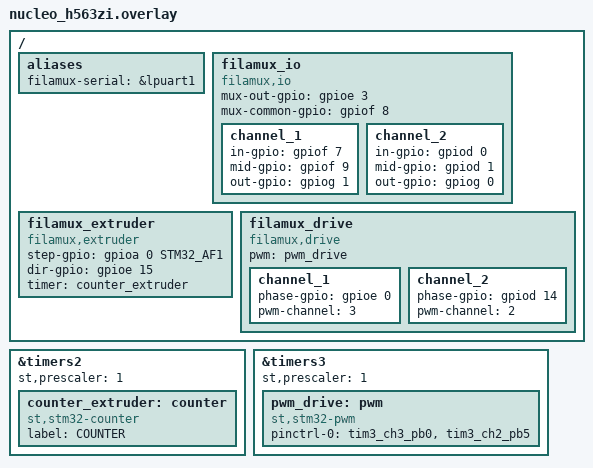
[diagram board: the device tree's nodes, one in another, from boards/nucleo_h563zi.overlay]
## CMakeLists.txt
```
#-------------------------------------------------------------------------------
# Zephyr Example Application
#
# Copyright (c) 2021 Nordic Semiconductor ASA
# SPDX-License-Identifier: Apache-2.0

cmake_minimum_required(VERSION 3.13.1)
find_package(Zephyr REQUIRED HINTS $ENV{ZEPHYR_BASE})

project(app LANGUAGES C)

target_sources(app 
    PRIVATE 
        src/main.c
        src/filamux.c
        src/filamux_io.c
        src/filamux_extruder.c
        src/filamux_serial.c
        src/filamux_counter.c
        src/state_machine.c
        src/filament_drive.c
)
```

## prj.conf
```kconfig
# Copyright (c) 2021 Nordic Semiconductor ASA
# SPDX-License-Identifier: Apache-2.0
#
# This file contains selected Kconfig options for the application.

CONFIG_DEBUG=y
CONFIG_LOG=y
CONFIG_APP_LOG_LEVEL_INF=y

CONFIG_MAIN_STACK_SIZE=4096

CONFIG_SMF=y
CONFIG_FILAMUX_PROTO_LIB=y
CONFIG_SERIAL=y
CONFIG_UART_INTERRUPT_DRIVEN=y
CONFIG_COUNTER=y
CONFIG_PWM=y
CONFIG_CRC=y
```

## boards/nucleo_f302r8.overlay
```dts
/*
 * Copyright (c) 2021 Nordic Semiconductor ASA
 * SPDX-License-Identifier: Apache-2.0
 */

/* This devicetree overlay file will be automatically picked by the Zephyr
 * build system when building the sample for the nucleo_f302r8 board. It shows
 * how the example-application can be built on sample boards already provided
 * by Zephyr.
 */

/ {
};

&gpioc {
	status = "okay";
};
```

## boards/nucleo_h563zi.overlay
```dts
#include <zephyr/dt-bindings/pinctrl/stm32-pinctrl.h>

/ {
    aliases {
        filamux-serial = &lpuart1;
    };

    filamux_io: filamux_io {
        compatible = "filamux,io";
        mux-out-gpio = <&gpioe 3 0>;
        mux-common-gpio = <&gpiof 8 0>;
        channel_1 {
            in-gpio = <&gpiof 7 0>;
            mid-gpio = <&gpiof 9 0>;
            out-gpio = <&gpiog 1 0>;
        };
        channel_2 {
            in-gpio = <&gpiod 0 0>;
            mid-gpio = <&gpiod 1 0>;
            out-gpio = <&gpiog 0 0>;
        };
    };

    filamux_extruder: filamux_extruder {
        compatible = "filamux,extruder";
        step-gpio = <&gpioa 0 STM32_AF1>; ///< TIM2_CH1
        dir-gpio = <&gpioe 15 0>;
        timer = <&counter_extruder>;
    };

    filamux_drive: filamux_drive {
        compatible = "filamux,drive";
        pwm = <&pwm_drive>;
        channel_1 {
            phase-gpio = <&gpioe 0 0>;
            pwm-channel = <3>;
        };
        channel_2 {
            phase-gpio = <&gpiod 14 0>;
            pwm-channel = <2>;
        };
    };
};

&timers2 {
    status = "okay";
    st,prescaler = <1>;
    counter_extruder: counter {
        compatible = "st,stm32-counter";
        status = "okay";
        label = "COUNTER";
    };
};

&timers3 {
    status = "okay";
    st,prescaler = <1>;
    pwm_drive: pwm {
        compatible = "st,stm32-pwm";
        status = "okay";
        pinctrl-0 = <&tim3_ch3_pb0 &tim3_ch2_pb5>;
        pinctrl-names = "default";
    };
};
```

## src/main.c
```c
/*
 * Copyright (c) 2021 Nordic Semiconductor ASA
 * SPDX-License-Identifier: Apache-2.0
 */

#include <zephyr/kernel.h>
#include <app_version.h>

#include <zephyr/logging/log.h>
LOG_MODULE_REGISTER(main, CONFIG_APP_LOG_LEVEL);

#include "filamux_counter.h"
#include "filamux.h"
#include "filamux_serial.h"
#include "filamux_io.h"
#include "state_machine.h"

void extruder_demo(struct filamux *filamux)
{
	filamux_extruder_set_speed(filamux->extruder, 1.0);
	k_sleep(K_MSEC(3000));
	LOG_INF("Feeding 10mm");
	filamux_extruder_feed(filamux->extruder, 100);
	k_sleep(K_MSEC(3000));
	LOG_INF("Feeding -5mm");
	filamux_extruder_set_speed(filamux->extruder, 0.5);
	filamux_extruder_feed(filamux->extruder, -50);
	k_sleep(K_MSEC(3000));
	LOG_INF("Feeding 20mm");
	filamux_extruder_set_speed(filamux->extruder, 2.0);
	filamux_extruder_feed(filamux->extruder, 200);
}

void drive_demo(struct filamux *filamux)
{
	LOG_INF("Setting drive to 1");
	set_active_filament_drive(filamux->drive, 1);
	set_filament_drive_feed(filamux->drive, 50);
	k_sleep(K_MSEC(1000));
	set_filament_drive_feed(filamux->drive, 100);
	k_sleep(K_MSEC(1000));
	set_filament_drive_feed(filamux->drive, -50);
	k_sleep(K_MSEC(1000));
	LOG_INF("Setting drive to 2");
	set_active_filament_drive(filamux->drive, 2);
	set_filament_drive_feed(filamux->drive, 50);
	k_sleep(K_MSEC(1000));
	set_filament_drive_feed(filamux->drive, 100);
	k_sleep(K_MSEC(1000));
	set_filament_drive_feed(filamux->drive, -50);
	k_sleep(K_MSEC(1000));
}

int main(void)
{
	int ret;

	printk("Zephyr Example Application %s\n", APP_VERSION_STRING);

	struct filamux *filamux = NULL;
	filamux_init(&filamux);
	LOG_INF("Initializing serial");
	filamux_serial_init(filamux);
	LOG_INF("Initializing io");
	io_init();
	set_filament_drive_feed(filamux->drive, 0);
	filamux_counter_set_current_spool(filamux->counter, 1);

	while (1) {
		filamux_fsm_run(filamux);
		// filamux_extruder_feed_continuous(filamux->extruder, -5);
		// drive_demo(filamux);
		//  extruder_demo(filamux);
		filamux_serial_process(filamux);
		k_msleep(100);

		/* Counting */
		filamux_counter_add(filamux->counter,
				    -filamux_extruder_pop_traveled_mm(filamux->extruder));
	}

	return 0;
}
```

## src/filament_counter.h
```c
#ifndef __FILAMENT_COUNTER_H_
#define __FILAMENT_COUNTER_H_

struct filament_counter;

/**
 * Allocate new filament counter
 */
int new_filament_counter(struct filament_counter **counter, unsigned int spools_count);

/**
 * Get used length of current filament spool
 * @returns -1 if no spool selected
 */
int get_current_filament_used(struct filament_counter *counter);

/**
 * Get used length of specified filament spool
 * @param index index of filament spool to fetch
 */
int get_filament_used(struct filament_counter *counter, unsigned int index);

/**
 * Set current spool to index
 * @param index which spool is used now
 */
int set_current_spool(struct filament_counter *counter, unsigned int index);

/**
 * Get current spool
 * @returns 0 if no spool selected
 */
int get_current_spool(struct filament_counter *counter);

#endif /* __FILAMENT_COUNTER_H_ */
```

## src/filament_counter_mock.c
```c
#include "filament_counter.h"
#include <stdint.h>
#include <zephyr/logging/log.h>
LOG_MODULE_REGISTER(counter, CONFIG_APP_LOG_LEVEL);

struct spool {
	unsigned int index;
	uint32_t used_length; ///< In mm
};

struct filament_counter {
	struct spool *current_spool; ///< Current spool. NULL means no spool.
	unsigned int spool_count;    ///< Number of spools
	struct spool *spools;
};

int new_filament_counter(struct filament_counter **counter, unsigned int spools_count)
{
	*counter = malloc(sizeof(struct filament_counter));
	if (!counter) {
		LOG_ERR("Could not allocate filament counter");
		return -1;
	}
	(*counter)->current_spool = NULL;
	(*counter)->spools = malloc(sizeof(struct spool[spools_count]));
	if (!(*counter)->spools) {
		LOG_ERR("Could not allocate spool buffers");
		return -1;
	}
	(*counter)->spool_count = spools_count;

	struct spool *spool = (*counter)->spools;
	for (int i = 0; i < spools_count; i++) {
		spool->index = i + 1;
		spool->used_length = 0;
		spool++;
	}

	return 0;
}

int get_current_filament_used(struct filament_counter *counter)
{
	if (!counter->current_spool) {
		LOG_ERR("No spool selected. Cannot get used length");
		return -1;
	}
	return counter->current_spool->used_length;
}

int get_filament_used(struct filament_counter *counter, unsigned int index)
{
	if (index > counter->spool_count || index == 0) {
		LOG_ERR("Invalid spool index: %d", index);
		return -1;
	}
	return counter->spools[index - 1].used_length;
}

int set_current_spool(struct filament_counter *counter, unsigned int index)
{
	if (index > counter->spool_count || index == 0) {
		LOG_ERR("Invalid spool index: %d", index);
		return -1;
	}
	counter->current_spool = &counter->spools[index - 1];
	LOG_INF("Current spool set to %d", index);
	return 0;
}

int get_current_spool(struct filament_counter *counter)
{
	if (!counter->current_spool) {
		return 0;
	}
	return counter->current_spool->index;
}
```

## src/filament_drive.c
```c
#include "filament_drive.h"
#include <zephyr/drivers/gpio.h>
#include <zephyr/drivers/pwm.h>
#include <zephyr/logging/log.h>
#include <stdlib.h>
LOG_MODULE_REGISTER(drive, CONFIG_APP_LOG_LEVEL);

struct filament_drive_channel {
	struct gpio_dt_spec ph_gpio;
	int pwm_channel;
};

struct filament_drive {
	unsigned int active_drive;
	unsigned int drive_count;

	struct filament_drive_channel *channel_active;
};

#define CHANNEL_DATA(node_id)                                                                      \
	{                                                                                          \
		.ph_gpio = GPIO_DT_SPEC_GET(node_id, phase_gpio),                                  \
		.pwm_channel = DT_PROP(node_id, pwm_channel),                                      \
	},

static struct filament_drive_channel channels[] = {
	DT_FOREACH_CHILD(DT_NODELABEL(filamux_drive), CHANNEL_DATA)};

static const struct device *pwm = DEVICE_DT_GET(DT_NODELABEL(pwm_drive));

int new_filament_drive(struct filament_drive **drive, unsigned int drive_count)
{
	*drive = malloc(sizeof(struct filament_drive));
	(*drive)->active_drive = 0;
	(*drive)->drive_count = sizeof(channels) / sizeof(struct filament_drive_channel);
	(*drive)->channel_active = NULL;
	gpio_pin_configure_dt(&channels[0].ph_gpio, GPIO_OUTPUT | GPIO_PUSH_PULL);
	gpio_pin_configure_dt(&channels[1].ph_gpio, GPIO_OUTPUT | GPIO_PUSH_PULL);
	return 0;
}

int get_active_filament_drive(struct filament_drive *drive)
{
	/* TODO check gpios */
	return drive->active_drive;
}

int set_active_filament_drive(struct filament_drive *drive, int drive_number)
{
	LOG_DBG("Setting filament drive to: %d", drive_number);
	if (drive_number < 0 || drive_number > drive->drive_count) {
		LOG_ERR("Invalid drive number: %d", drive_number);
		return -1;
	}
	if (drive->active_drive != 0) {
		LOG_DBG("Stopping current drive");
		set_filament_drive_feed(drive, 0);
	}
	drive->active_drive = drive_number;
	if (drive_number == 0) {
		drive->channel_active = NULL;
	} else {
		drive->channel_active = &channels[drive_number - 1];
	}
	LOG_DBG("Set active drive to %d", drive_number);
	return 0;
}

int set_filament_drive_feed(struct filament_drive *drive, int feed)
{
	if (drive->active_drive <= 0) {
		LOG_ERR("Cannot set drive feed when no drive is active");
		return -1;
	}
	if (drive->channel_active == NULL) {
		LOG_ERR("Cannot set drive. channel_active == NULL");
		return -1;
	}
	LOG_INF("Setting filament drive feed to %d", feed);
	bool is_reverse = feed < 0;
	unsigned int feed_abs = abs(feed);
	const uint32_t period = 10000;
	uint32_t pulse_width = period;
	if (feed_abs > 100) {
		LOG_ERR("cannot set feed to %d%. Capping to 100%");
	} else {
		LOG_DBG("Set feed to %d", feed);
		pulse_width = (feed_abs / 100.0) * period;
	}
	gpio_pin_set_dt(&drive->channel_active->ph_gpio, is_reverse);
	pwm_set(pwm, drive->channel_active->pwm_channel, period, pulse_width, PWM_POLARITY_NORMAL);
	return 0;
}
```

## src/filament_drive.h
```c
#ifndef __FILAMENT_DRIVE_H_
#define __FILAMENT_DRIVE_H_

#include "filamux.h"

struct filament_drive;

int new_filament_drive(struct filament_drive **drive, unsigned int drive_count);

/**
 * Check which filament drive is active
 * @returns active drive number. 0 if no drive active.
 */
int get_active_filament_drive(struct filament_drive *drive);

/**
 * Set active filament drive
 * @param drive_number number of drive to be activated. 0 to disable actieve drive.
 */
int set_active_filament_drive(struct filament_drive *drive, int drive_number);

/**
 * Set filament drive feed speed.
 * @param feed 0-100% of speed.
 */
int set_filament_drive_feed(struct filament_drive *drive, int feed);

#endif /* __FILAMENT_DRIVE_H_ */
```

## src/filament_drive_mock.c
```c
#include "filament_drive.h"
#include <zephyr/logging/log.h>
#include <stdlib.h>
LOG_MODULE_REGISTER(drive, CONFIG_APP_LOG_LEVEL);

struct filament_drive {
	unsigned int active_drive;
	unsigned int drive_count;
};

int new_filament_drive(struct filament_drive **drive, unsigned int drive_count)
{
	*drive = malloc(sizeof(struct filament_drive));
	(*drive)->active_drive = 0;
	(*drive)->drive_count = drive_count;
	return 0;
}

int get_active_filament_drive(struct filament_drive *drive)
{
	return drive->active_drive;
}

int set_active_filament_drive(struct filament_drive *drive, int drive_number)
{
	if (drive_number == 0 || drive_number > drive->drive_count) {
		LOG_ERR("Invalid drive number: %d", drive_number);
		return -1;
	}
	drive->active_drive = drive_number;
	LOG_DBG("Set active drive to %d", drive_number);
	return 0;
}

int set_filament_drive_feed(struct filament_drive *drive, int feed)
{
	LOG_DBG("Set feed to %d", feed);
	return 0;
}
```

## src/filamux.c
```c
#include "filamux.h"
#include <zephyr/logging/log.h>
LOG_MODULE_REGISTER(core, CONFIG_APP_LOG_LEVEL);

#define SPOOLS_COUNT 2

int filamux_init(struct filamux **o)
{
	*o = malloc(sizeof(struct filamux));
	new_filament_counter(&(*o)->counter, SPOOLS_COUNT);
	new_filament_drive(&(*o)->drive, SPOOLS_COUNT);
	filamux_extruder_init(&(*o)->extruder);
	filamux_fsm_init(*o);

	/* TODO set target spool to current from IO */
	(*o)->target_spool = 0;

	(*o)->extruder_req.distance = 0;
	(*o)->extruder_req.speed = 0;
	return 0;
}

int filamux_set_target_spool(struct filamux *o, unsigned int target_spool)
{
	if (target_spool > SPOOLS_COUNT) {
		LOG_ERR("Cannot set target spool to: %d. Out of range");
		return -ERANGE;
	}
	o->target_spool = target_spool;
	LOG_INF("Set target spool to %d", o->target_spool);
	return 0;
}

int filamux_feed_extruder(struct filamux *o, int speed, int distance)
{
	o->extruder_req.speed = speed;
	o->extruder_req.distance = distance;
	return 0;
}
```

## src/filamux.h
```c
#include "state_machine.h"
#include "filamux_counter.h"
#include "filament_drive.h"
#include "filamux_extruder.h"

#ifndef __FILAMUX_H_
#define __FILAMUX_H_

struct filamux {
	struct filament_counter *counter;
	struct filament_drive *drive;
	struct filamux_extruder *extruder;
	struct main_fsm_object *fsm;

	unsigned int target_spool;

	struct {
		int distance;
		int speed;
	} extruder_req;
};

int filamux_init(struct filamux **o);

/**
 * @brief Set target spool
 * @returns 0 on success
 * @returns -ERANGE if spool out of range
 */
int filamux_set_target_spool(struct filamux *o, unsigned int target_spool);

/**
 * @brief Request extruder feed
 * @returns 0 on success
 */
int filamux_feed_extruder(struct filamux *o, int speed, int distance);

#endif /* __FILAMUX_H_ */
```

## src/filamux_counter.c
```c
#include "filamux_counter.h"
#include <stdint.h>
#include <zephyr/logging/log.h>
#include <stdlib.h>
LOG_MODULE_REGISTER(counter, CONFIG_APP_LOG_LEVEL);

struct spool {
	unsigned int index;
	int length; ///< In mm
};

struct filamux_counter {
	struct spool *current_spool; ///< Current spool. NULL means no spool.
	unsigned int spool_count;    ///< Number of spools
	struct spool *spools;
};

int new_filament_counter(struct filamux_counter **counter, unsigned int spools_count)
{
	*counter = malloc(sizeof(struct filamux_counter));
	if (!counter) {
		LOG_ERR("Could not allocate filament counter");
		return -1;
	}
	(*counter)->current_spool = NULL;
	(*counter)->spools = malloc(sizeof(struct spool[spools_count]));
	if (!(*counter)->spools) {
		LOG_ERR("Could not allocate spool buffers");
		return -1;
	}
	(*counter)->spool_count = spools_count;

	struct spool *spool = (*counter)->spools;
	for (int i = 0; i < spools_count; i++) {
		spool->index = i + 1;
		spool->length = 0;
		spool++;
	}

	return 0;
}

int filamux_counter_get_current_filament_length(struct filamux_counter *counter)
{
	if (!counter->current_spool) {
		LOG_ERR("No spool selected. Cannot get used length");
		return -1;
	}
	return counter->current_spool->length;
}

int filamux_counter_get_filament_length(struct filamux_counter *counter, unsigned int index)
{
	if (index > counter->spool_count || index == 0) {
		LOG_ERR("Invalid spool index: %d", index);
		return -1;
	}
	return counter->spools[index - 1].length;
}

int filamux_counter_set_current_spool(struct filamux_counter *counter, unsigned int index)
{
	if (index > counter->spool_count || index == 0) {
		LOG_ERR("Invalid spool index: %d", index);
		return -1;
	}
	counter->current_spool = &counter->spools[index - 1];
	LOG_INF("Current spool set to %d", index);
	return 0;
}

int filamux_counter_get_current_spool(struct filamux_counter *counter)
{
	if (!counter->current_spool) {
		return 0;
	}
	return counter->current_spool->index;
}

int filamux_counter_add(struct filamux_counter *counter, int value)
{
	if (!counter->current_spool) {
		LOG_ERR("Cannot add to spool length. No spool selected");
		return -1;
	}
	counter->current_spool->length += value;

	return 0;
}
```

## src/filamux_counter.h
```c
#ifndef __FILAMUX_COUNTER_H_
#define __FILAMUX_COUNTER_H_

struct filamux_counter;

/**
 * Allocate new filament counter
 */
int new_filamux_counter(struct filamux_counter **counter, unsigned int spools_count);

/**
 * Get length of current filament spool
 * @returns -1 if no spool selected
 */
int filamux_counter_get_current_filament_length(struct filamux_counter *counter);

/**
 * Get length of specified filament spool
 * @param index index of filament spool to fetch
 */
int filamux_counter_get_filament_length(struct filamux_counter *counter, unsigned int index);

/**
 * Set current spool to index
 * @param index which spool is used now
 */
int filamux_counter_set_current_spool(struct filamux_counter *counter, unsigned int index);

/**
 * Get current spool
 * @returns 0 if no spool selected
 */
int filamux_counter_get_current_spool(struct filamux_counter *counter);

/**
 * Add value to current spool length
 */
int filamux_counter_add(struct filamux_counter *counter, int value);

#endif /* __FILAMUX_COUNTER_H_ */
```

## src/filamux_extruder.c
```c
#include "filamux_extruder.h"
#include <zephyr/kernel.h>
#include <zephyr/drivers/gpio.h>
#include <zephyr/drivers/counter.h>
#include <zephyr/logging/log.h>
#include <stdlib.h>
LOG_MODULE_REGISTER(extruder, CONFIG_APP_LOG_LEVEL);

static const struct gpio_dt_spec step_gpio =
	GPIO_DT_SPEC_GET(DT_NODELABEL(filamux_extruder), step_gpio);
static const struct gpio_dt_spec dir_gpio =
	GPIO_DT_SPEC_GET(DT_NODELABEL(filamux_extruder), dir_gpio);
static const struct device *timer = DEVICE_DT_GET(DT_NODELABEL(counter_extruder));

const int E_STEPS = 415;

enum extruder_mode {
	EXTRUDER_MODE_STEP = 1,  ///< Count set amount of steps
	EXTRUDER_MODE_CONTINUOUS ///< Extruder continuously feeds with set speed
};

struct filamux_extruder {
	bool feeding_forward;
	uint32_t remaining_steps;
	enum extruder_mode mode;

	int speed;
	int steps_buffer; ///< For counting steps before passing 1mm or -1mm
	int mm_travelled; ///< mm traveled since last invocation of pop_traveled_mm
};

static void irq_extruder_timer(const struct device *timer, uint8_t ch, uint32_t ticks,
			       void *user_data)
{
	LOG_INF("Extruder IRQ. Channel: %d Ticks: %d", ch, ticks);
}

static void irq_handler(const struct device *dev, void *user_data)
{
	struct filamux_extruder *extruder = (struct filamux_extruder *)user_data;
	if (extruder->remaining_steps > 0 || extruder->mode == EXTRUDER_MODE_CONTINUOUS) {
		gpio_pin_toggle_dt(&step_gpio);

		if (gpio_pin_get_dt(&step_gpio)) {
			if (extruder->mode == EXTRUDER_MODE_STEP) {
				if (--extruder->remaining_steps <= 0) {
					extruder->speed = 0;
				}
			}

			/* Count steps */
			extruder->steps_buffer += extruder->feeding_forward;
			if (extruder->steps_buffer >= E_STEPS) {
				extruder->steps_buffer = 0;
				extruder->mm_travelled += extruder->feeding_forward;
			}
		}
	}
}

static void set_dir_pin(struct filamux_extruder *extruder, bool state)
{
	extruder->feeding_forward = state;
	gpio_pin_set_dt(&dir_gpio, state);
}

int filamux_extruder_init(struct filamux_extruder **extruder)
{
	*extruder = malloc(sizeof(struct filamux_extruder));
	(*extruder)->remaining_steps = 0;
	(*extruder)->feeding_forward = true;
	(*extruder)->mm_travelled = 0;
	(*extruder)->steps_buffer = 0;
	(*extruder)->mode = EXTRUDER_MODE_STEP;

	if (!gpio_is_ready_dt(&step_gpio)) {
		LOG_ERR("Step pin not ready");
		return -1;
	}
	if (!gpio_is_ready_dt(&dir_gpio)) {
		LOG_ERR("Step pin not ready");
		return -1;
	}
	if (!device_is_ready(timer)) {
		LOG_ERR("Timer not ready");
		return -1;
	}

	gpio_pin_configure_dt(&step_gpio, GPIO_OUTPUT | GPIO_PUSH_PULL);
	gpio_pin_configure_dt(&dir_gpio, GPIO_OUTPUT | GPIO_PUSH_PULL);

	filamux_extruder_set_speed(*extruder, 1);
	counter_start(timer);
	return 0;
}

int filamux_extruder_set_speed(struct filamux_extruder *extruder, float speed)
{
	LOG_DBG("Setting extrusion speed to %.02f", speed);
	extruder->speed = (int)speed;
	float period = 1 / fabs(speed);
	struct counter_top_cfg timer_cfg = {.callback = irq_handler,
					    .flags = 0,
					    .ticks = counter_us_to_ticks(timer, period * 1000),
					    .user_data = extruder};
	counter_set_top_value(timer, &timer_cfg);
	return 0;
}

int filamux_extruder_feed(struct filamux_extruder *extruder, float mm)
{
	LOG_DBG("Feeding %.02f mm", mm);
	extruder->mode = EXTRUDER_MODE_STEP;
	set_dir_pin(extruder, mm > 0);
	extruder->remaining_steps = fabs(mm) * E_STEPS;
	return 0;
}

int filamux_extruder_feed_continuous(struct filamux_extruder *extruder, float speed)
{
	LOG_INF("Extruder feeding continously %.02f", speed);
	extruder->mode = EXTRUDER_MODE_CONTINUOUS;
	set_dir_pin(extruder, speed > 0);
	filamux_extruder_set_speed(extruder, fabs(speed));
}

int filamux_extruder_pop_traveled_mm(struct filamux_extruder *extruder)
{
	int traveled_mm = extruder->mm_travelled;
	extruder->mm_travelled = 0;
	return traveled_mm;
}

int filamux_extruder_get_speed(struct filamux_extruder *extruder)
{
	return extruder->speed;
}
```

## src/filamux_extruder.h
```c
#ifndef __FILAMUX_EXTRUDER_H_
#define __FILAMUX_EXTRUDER_H_

struct filamux_extruder;

int filamux_extruder_init(struct filamux_extruder **extruder);

/**
 * Set extrusion speed
 * @param speed mm/s
 */
int filamux_extruder_set_speed(struct filamux_extruder *extruder, float speed);

/**
 * Feed set amount of milimeters
 */
int filamux_extruder_feed(struct filamux_extruder *extruder, float mm);

/**
 * Start extruding with set speed
 */
int filamux_extruder_feed_continuous(struct filamux_extruder *extruder, float speed);

/**
 * Get travelled mm and clear internal buffer
 * @returns number of mm travelled since last invocation of this function
 */
int filamux_extruder_pop_traveled_mm(struct filamux_extruder *extruder);

/**
 * Get current speed of extruder
 * @returns current speed in mm/s
 */
int filamux_extruder_get_speed(struct filamux_extruder *extruder);

#endif /* __FILAMUX_EXTRUDER_H_ */
```

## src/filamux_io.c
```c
#include "filamux_io.h"
#include <zephyr/kernel.h>
#include <zephyr/drivers/gpio.h>

static const struct gpio_dt_spec mux_out = GPIO_DT_SPEC_GET(DT_NODELABEL(filamux_io), mux_out_gpio);

void io_init()
{
	gpio_pin_configure_dt(&mux_out, GPIO_ACTIVE_HIGH);
}

bool io_get_mux_out()
{
	return gpio_pin_get_dt(&mux_out);
}

bool io_get_mux_common()
{
	return false;
}

bool io_get_mux(unsigned int output, enum mux_sensor_type)
{
	return false;
}

bool io_get_cam(unsigned int output)
{
	return false;
}
```
